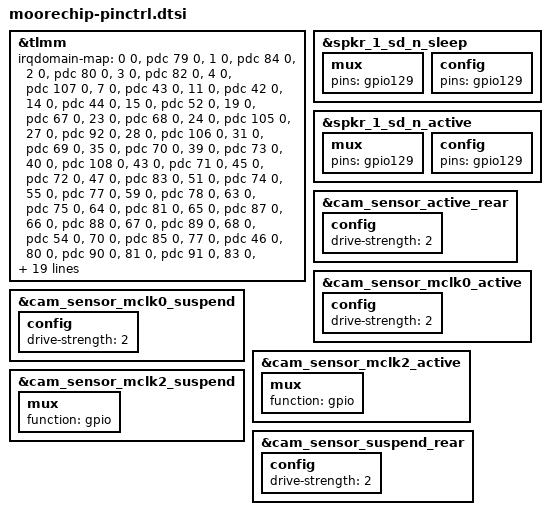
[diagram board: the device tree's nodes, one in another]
&tlmm {
	irqdomain-map = <0 0 &pdc 79 0>,
			<1 0 &pdc 84 0>,
			<2 0 &pdc 80 0>,
			<3 0 &pdc 82 0>,
			<4 0 &pdc 107 0>,
			<7 0 &pdc 43 0>,
			<11 0 &pdc 42 0>,
			<14 0 &pdc 44 0>,
			<15 0 &pdc 52 0>,
			<19 0 &pdc 67 0>,
			<23 0 &pdc 68 0>,
			<24 0 &pdc 105 0>,
			<27 0 &pdc 92 0>,
			<28 0 &pdc 106 0>,
			<31 0 &pdc 69 0>,
			<35 0 &pdc 70 0>,
			<39 0 &pdc 73 0>,
			<40 0 &pdc 108 0>,
			<43 0 &pdc 71 0>,
			<45 0 &pdc 72 0>,
			<47 0 &pdc 83 0>,
			<51 0 &pdc 74 0>,
			<55 0 &pdc 77 0>,
			<59 0 &pdc 78 0>,
			<63 0 &pdc 75 0>,
			<64 0 &pdc 81 0>,
			<65 0 &pdc 87 0>,
			<66 0 &pdc 88 0>,
			<67 0 &pdc 89 0>,
			<68 0 &pdc 54 0>,
			<70 0 &pdc 85 0>,
			<77 0 &pdc 46 0>,
			<80 0 &pdc 90 0>,
			<81 0 &pdc 91 0>,
			<83 0 &pdc 97 0>,
			<84 0 &pdc 98 0>,
			<86 0 &pdc 99 0>,
			<88 0 &pdc 101 0>,
			<89 0 &pdc 102 0>,
			<92 0 &pdc 103 0>,
			<93 0 &pdc 104 0>,
			<100 0 &pdc 53 0>,
			<103 0 &pdc 47 0>,
			<104 0 &pdc 48 0>,
			<108 0 &pdc 49 0>,
			<109 0 &pdc 94 0>,
			<110 0 &pdc 95 0>,
			<111 0 &pdc 96 0>,
			<112 0 &pdc 55 0>,
			<113 0 &pdc 56 0>,
			<118 0 &pdc 50 0>,
			<121 0 &pdc 51 0>,
			<122 0 &pdc 57 0>,
			<123 0 &pdc 58 0>,
			<124 0 &pdc 45 0>,
			<126 0 &pdc 59 0>,
			<128 0 &pdc 76 0>,
			<129 0 &pdc 86 0>,
			<132 0 &pdc 93 0>,
			<133 0 &pdc 65 0>,
			<134 0 &pdc 66 0>,
			<136 0 &pdc 62 0>,
			<137 0 &pdc 63 0>,
			<138 0 &pdc 64 0>,
			<142 0 &pdc 60 0>,
			<143 0 &pdc 61 0>,
			<147 0 &pdc 109 0>, /* bi_mx_lpass_1_aoss_mx  */
			<150 0 &pdc 110 0>,
			<157 0 &pdc 111 0>,
			<158 0 &pdc 112 0>,
			<160 0 &pdc 113 0>,
			<162 0 &pdc 114 0>,
			<164 0 &pdc 115 0>,
			<166 0 &pdc 116 0>,
			<167 0 &pdc 117 0>,
			<175 0 &pdc 118 0>,
			<177 0 &pdc 119 0>,
			<179 0 &pdc 120 0>;
};

/* Audio */
&spkr_1_sd_n_sleep {
	mux {
		pins = "gpio129";
	};

	config {
		pins = "gpio129";
	};
};

&spkr_1_sd_n_active {
	mux {
		pins = "gpio129";
	};

	config {
		pins = "gpio129";
	};
};

/* Camera */
&cam_sensor_active_rear {
	config {
		drive-strength = <2>;
	};
};

&cam_sensor_mclk0_active {
	config {
		drive-strength = <2>;
	};
};

&cam_sensor_mclk0_suspend {
	config {
		drive-strength = <2>;
	};
};

&cam_sensor_mclk2_active {
	mux {
		function = "gpio";
	};
};

&cam_sensor_mclk2_suspend {
	mux {
		function = "gpio";
	};
};

&cam_sensor_suspend_rear {
	config {
		drive-strength = <2>;
	};
};
